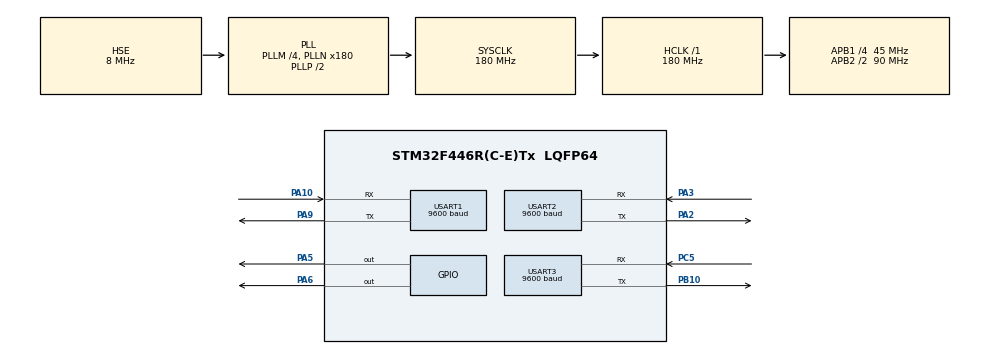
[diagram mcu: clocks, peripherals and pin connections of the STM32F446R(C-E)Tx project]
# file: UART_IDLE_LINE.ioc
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Dma.Request0=USART1_RX
Dma.Request1=USART3_RX
Dma.USART1_RX.0.Direction=DMA_PERIPH_TO_MEMORY
Dma.USART1_RX.0.FIFOMode=DMA_FIFOMODE_DISABLE
Dma.USART1_RX.0.Instance=DMA2_Stream2
Dma.USART1_RX.0.MemDataAlignment=DMA_MDATAALIGN_BYTE
Dma.USART1_RX.0.MemInc=DMA_MINC_ENABLE
Dma.USART1_RX.0.Mode=DMA_NORMAL
Dma.USART1_RX.0.PeriphDataAlignment=DMA_PDATAALIGN_BYTE
Dma.USART1_RX.0.PeriphInc=DMA_PINC_DISABLE
Dma.USART1_RX.0.Priority=DMA_PRIORITY_LOW
Dma.USART3_RX.1.Direction=DMA_PERIPH_TO_MEMORY
Dma.USART3_RX.1.FIFOMode=DMA_FIFOMODE_DISABLE
Dma.USART3_RX.1.Instance=DMA1_Stream1
Dma.USART3_RX.1.MemDataAlignment=DMA_MDATAALIGN_BYTE
Dma.USART3_RX.1.MemInc=DMA_MINC_ENABLE
Dma.USART3_RX.1.Mode=DMA_NORMAL
Dma.USART3_RX.1.PeriphDataAlignment=DMA_PDATAALIGN_BYTE
Dma.USART3_RX.1.PeriphInc=DMA_PINC_DISABLE
Dma.USART3_RX.1.Priority=DMA_PRIORITY_LOW
IWDG.Prescaler=IWDG_PRESCALER_256
IWDG.Reload=2499
Mcu.Family=STM32F4
Mcu.Name=STM32F446R(C-E)Tx
Mcu.Package=LQFP64
NVIC.DMA1_Stream1_IRQn=true\:0\:0\:false\:false\:true\:false\:true\:true
NVIC.DMA2_Stream2_IRQn=true\:0\:0\:false\:false\:true\:false\:true\:true
NVIC.PriorityGroup=NVIC_PRIORITYGROUP_0
NVIC.USART1_IRQn=true\:0\:0\:false\:false\:true\:true\:true\:true
NVIC.USART3_IRQn=true\:0\:0\:false\:false\:true\:true\:true\:true
PA10.Mode=Asynchronous
PA10.Signal=USART1_RX
PA2.Mode=Asynchronous
PA2.Signal=USART2_TX
PA3.Mode=Asynchronous
PA3.Signal=USART2_RX
PA5.Signal=GPIO_Output
PA6.Signal=GPIO_Output
PA9.Mode=Asynchronous
PA9.Signal=USART1_TX
PB10.Mode=Asynchronous
PB10.Signal=USART3_TX
PC5.Mode=Asynchronous
PC5.Signal=USART3_RX
PH0-OSC_IN.Mode=HSE-External-Oscillator
PH0-OSC_IN.Signal=RCC_OSC_IN
PH1-OSC_OUT.Mode=HSE-External-Oscillator
PH1-OSC_OUT.Signal=RCC_OSC_OUT
ProjectManager.HeapSize=0x200
ProjectManager.StackSize=0x400
ProjectManager.TargetToolchain=STM32CubeIDE
RCC.48MHZClocksFreq_Value=84000000
RCC.AHBFreq_Value=180000000
RCC.APB1CLKDivider=RCC_HCLK_DIV4
RCC.APB1Freq_Value=45000000
RCC.APB1TimFreq_Value=90000000
RCC.APB2CLKDivider=RCC_HCLK_DIV2
RCC.APB2Freq_Value=90000000
RCC.APB2TimFreq_Value=180000000
RCC.CortexFreq_Value=180000000
RCC.FLatency-AdvancedSettings=FLASH_LATENCY_5
RCC.HCLKFreq_Value=180000000
RCC.HSE_VALUE=8000000
RCC.HSI_VALUE=16000000
RCC.PLLM=4
RCC.PLLN=180
RCC.PLLSourceVirtual=RCC_PLLSOURCE_HSE
RCC.SYSCLKFreq_VALUE=180000000
RCC.SYSCLKSource=RCC_SYSCLKSOURCE_PLLCLK
RCC.USBFreq_Value=180000000
RCC.VCOOutputFreq_Value=360000000
USART1.BaudRate=9600
USART1.VirtualMode=VM_ASYNC
USART2.BaudRate=9600
USART2.VirtualMode=VM_ASYNC
USART3.BaudRate=9600
USART3.VirtualMode=VM_ASYNC
VP_IWDG_VS_IWDG.Mode=IWDG_Activate
board=NUCLEO-F446RE

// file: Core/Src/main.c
/* USER CODE BEGIN Header */
/**
 ******************************************************************************
 * @file           : main.c
 * @brief          : Main program body
 ******************************************************************************
 * @attention
 *
 * Copyright (c) 2022 STMicroelectronics.
 * All rights reserved.
 *
 * This software is licensed under terms that can be found in the LICENSE file
 * in the root directory of this software component.
 * If no LICENSE file comes with this software, it is provided AS-IS.
 *
 ******************************************************************************
 */
/* USER CODE END Header */
#include "main.h"

/* USER CODE BEGIN Includes */

#include "GPS.h"
#include "SIM900.h"
/* USER CODE END Includes */

IWDG_HandleTypeDef hiwdg;

UART_HandleTypeDef huart1;
UART_HandleTypeDef huart2;
UART_HandleTypeDef huart3;
DMA_HandleTypeDef hdma_usart1_rx;
DMA_HandleTypeDef hdma_usart3_rx;

/* USER CODE BEGIN PV */
GpsInfo NEO;
/* USER CODE END PV */

void SystemClock_Config(void);
static void MX_GPIO_Init(void);
static void MX_DMA_Init(void);
static void MX_USART1_UART_Init(void);
static void MX_USART2_UART_Init(void);
static void MX_USART3_UART_Init(void);
static void MX_IWDG_Init(void);

int main(void)
{

  /* MCU Configuration--------------------------------------------------------*/

  /* Reset of all peripherals, Initializes the Flash interface and the Systick. */
  HAL_Init();

  /* Configure the system clock */
  SystemClock_Config();

  /* Initialize all configured peripherals */
  MX_GPIO_Init();
  MX_DMA_Init();
  MX_USART1_UART_Init();
  MX_USART2_UART_Init();
  MX_USART3_UART_Init();
  MX_IWDG_Init();
  /* USER CODE BEGIN 2 */
	Sim900Init(&huart3);
	GpsInit(&huart1);
	SetSim900InternetConnectivity();
  /* USER CODE END 2 */

  /* Infinite loop */
	while (1)
	{

    /* USER CODE BEGIN 3 */
		ReadGPSCordinate(&NEO);
		SIM900HttpRequest(SetURL,&NEO);
	}
  /* USER CODE END 3 */
}

void SystemClock_Config(void)
{
  RCC_OscInitTypeDef RCC_OscInitStruct = {0};
  RCC_ClkInitTypeDef RCC_ClkInitStruct = {0};

  /** Configure the main internal regulator output voltage
  */
  __HAL_RCC_PWR_CLK_ENABLE();
  __HAL_PWR_VOLTAGESCALING_CONFIG(PWR_REGULATOR_VOLTAGE_SCALE1);

  /** Initializes the RCC Oscillators according to the specified parameters
  * in the RCC_OscInitTypeDef structure.
  */
  RCC_OscInitStruct.OscillatorType = RCC_OSCILLATORTYPE_LSI|RCC_OSCILLATORTYPE_HSE;
  RCC_OscInitStruct.HSEState = RCC_HSE_ON;
  RCC_OscInitStruct.LSIState = RCC_LSI_ON;
  RCC_OscInitStruct.PLL.PLLState = RCC_PLL_ON;
  RCC_OscInitStruct.PLL.PLLSource = RCC_PLLSOURCE_HSE;
  RCC_OscInitStruct.PLL.PLLM = 4;
  RCC_OscInitStruct.PLL.PLLN = 180;
  RCC_OscInitStruct.PLL.PLLP = RCC_PLLP_DIV2;
  RCC_OscInitStruct.PLL.PLLQ = 2;
  RCC_OscInitStruct.PLL.PLLR = 2;
  if (HAL_RCC_OscConfig(&RCC_OscInitStruct) != HAL_OK)
  {
    Error_Handler();
  }

  /** Activate the Over-Drive mode
  */
  if (HAL_PWREx_EnableOverDrive() != HAL_OK)
  {
    Error_Handler();
  }

  /** Initializes the CPU, AHB and APB buses clocks
  */
  RCC_ClkInitStruct.ClockType = RCC_CLOCKTYPE_HCLK|RCC_CLOCKTYPE_SYSCLK
                              |RCC_CLOCKTYPE_PCLK1|RCC_CLOCKTYPE_PCLK2;
  RCC_ClkInitStruct.SYSCLKSource = RCC_SYSCLKSOURCE_PLLCLK;
  RCC_ClkInitStruct.AHBCLKDivider = RCC_SYSCLK_DIV1;
  RCC_ClkInitStruct.APB1CLKDivider = RCC_HCLK_DIV4;
  RCC_ClkInitStruct.APB2CLKDivider = RCC_HCLK_DIV2;

  if (HAL_RCC_ClockConfig(&RCC_ClkInitStruct, FLASH_LATENCY_5) != HAL_OK)
  {
    Error_Handler();
  }
}

static void MX_IWDG_Init(void)
{

  hiwdg.Instance = IWDG;
  hiwdg.Init.Prescaler = IWDG_PRESCALER_256;
  hiwdg.Init.Reload = 2499;
  if (HAL_IWDG_Init(&hiwdg) != HAL_OK)
  {
    Error_Handler();
  }

}

static void MX_USART1_UART_Init(void)
{

  huart1.Instance = USART1;
  huart1.Init.BaudRate = 9600;
  huart1.Init.WordLength = UART_WORDLENGTH_8B;
  huart1.Init.StopBits = UART_STOPBITS_1;
  huart1.Init.Parity = UART_PARITY_NONE;
  huart1.Init.Mode = UART_MODE_TX_RX;
  huart1.Init.HwFlowCtl = UART_HWCONTROL_NONE;
  huart1.Init.OverSampling = UART_OVERSAMPLING_16;
  if (HAL_UART_Init(&huart1) != HAL_OK)
  {
    Error_Handler();
  }

}

static void MX_USART2_UART_Init(void)
{

  huart2.Instance = USART2;
  huart2.Init.BaudRate = 9600;
  huart2.Init.WordLength = UART_WORDLENGTH_8B;
  huart2.Init.StopBits = UART_STOPBITS_1;
  huart2.Init.Parity = UART_PARITY_NONE;
  huart2.Init.Mode = UART_MODE_TX_RX;
  huart2.Init.HwFlowCtl = UART_HWCONTROL_NONE;
  huart2.Init.OverSampling = UART_OVERSAMPLING_16;
  if (HAL_UART_Init(&huart2) != HAL_OK)
  {
    Error_Handler();
  }

}

static void MX_USART3_UART_Init(void)
{

  huart3.Instance = USART3;
  huart3.Init.BaudRate = 9600;
  huart3.Init.WordLength = UART_WORDLENGTH_8B;
  huart3.Init.StopBits = UART_STOPBITS_1;
  huart3.Init.Parity = UART_PARITY_NONE;
  huart3.Init.Mode = UART_MODE_TX_RX;
  huart3.Init.HwFlowCtl = UART_HWCONTROL_NONE;
  huart3.Init.OverSampling = UART_OVERSAMPLING_16;
  if (HAL_UART_Init(&huart3) != HAL_OK)
  {
    Error_Handler();
  }

}

static void MX_DMA_Init(void)
{

  /* DMA controller clock enable */
  __HAL_RCC_DMA2_CLK_ENABLE();
  __HAL_RCC_DMA1_CLK_ENABLE();

  /* DMA interrupt init */
  /* DMA1_Stream1_IRQn interrupt configuration */
  HAL_NVIC_SetPriority(DMA1_Stream1_IRQn, 0, 0);
  HAL_NVIC_EnableIRQ(DMA1_Stream1_IRQn);
  /* DMA2_Stream2_IRQn interrupt configuration */
  HAL_NVIC_SetPriority(DMA2_Stream2_IRQn, 0, 0);
  HAL_NVIC_EnableIRQ(DMA2_Stream2_IRQn);

}

static void MX_GPIO_Init(void)
{
  GPIO_InitTypeDef GPIO_InitStruct = {0};

  /* GPIO Ports Clock Enable */
  __HAL_RCC_GPIOH_CLK_ENABLE();
  __HAL_RCC_GPIOA_CLK_ENABLE();
  __HAL_RCC_GPIOC_CLK_ENABLE();
  __HAL_RCC_GPIOB_CLK_ENABLE();

  /*Configure GPIO pin Output Level */
  HAL_GPIO_WritePin(GPIOA, GPIO_PIN_5|GPIO_PIN_6, GPIO_PIN_RESET);

  /*Configure GPIO pins : PA5 PA6 */
  GPIO_InitStruct.Pin = GPIO_PIN_5|GPIO_PIN_6;
  GPIO_InitStruct.Mode = GPIO_MODE_OUTPUT_PP;
  GPIO_InitStruct.Pull = GPIO_NOPULL;
  GPIO_InitStruct.Speed = GPIO_SPEED_FREQ_LOW;
  HAL_GPIO_Init(GPIOA, &GPIO_InitStruct);

}

void Error_Handler(void)
{
	__disable_irq();
	while (1)
	{
	}
}
